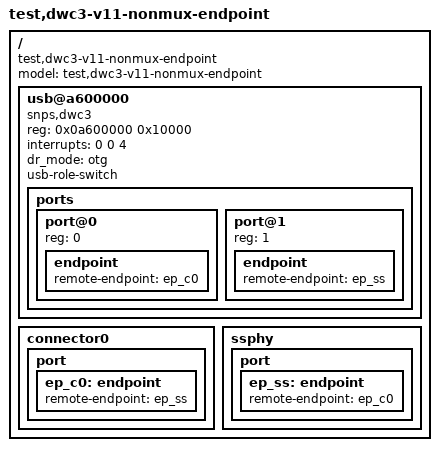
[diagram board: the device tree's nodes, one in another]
/dts-v1/;

/ {
	model = "test,dwc3-v11-nonmux-endpoint";
	compatible = "test,dwc3-v11-nonmux-endpoint";
	#address-cells = <1>;
	#size-cells = <1>;

	usb@a600000 {
		compatible = "snps,dwc3";
		reg = <0x0a600000 0x10000>;
		interrupts = <0 0 4>;
		dr_mode = "otg";
		usb-role-switch;

		ports {
			#address-cells = <1>;
			#size-cells = <0>;

			port@0 {
				reg = <0>;

				endpoint {
					remote-endpoint = <&ep_c0>;
				};
			};

			port@1 {
				reg = <1>;

				endpoint {
					remote-endpoint = <&ep_ss>;
				};
			};
		};
	};

	connector0 {
		port {
			ep_c0: endpoint {
				remote-endpoint = <&ep_ss>;
			};
		};
	};

	ssphy {
		port {
			ep_ss: endpoint {
				remote-endpoint = <&ep_c0>;
			};
		};
	};
};
